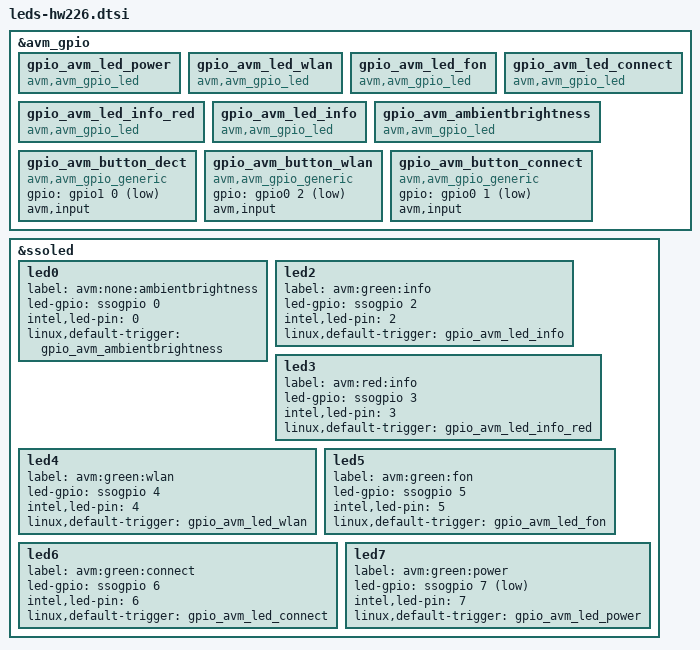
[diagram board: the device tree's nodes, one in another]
/* LEDs & Buttons für die 7590 und verwandte Boxen */

&avm_gpio {
	gpio_avm_led_power {
		compatible = "avm,avm_gpio_led";
	};
	gpio_avm_led_wlan {
		compatible = "avm,avm_gpio_led";
	};
	gpio_avm_led_fon {
		compatible = "avm,avm_gpio_led";
	};
	gpio_avm_led_connect {
		compatible = "avm,avm_gpio_led";
	};
	gpio_avm_led_info_red {
		compatible = "avm,avm_gpio_led";
	};
	gpio_avm_led_info {
		compatible = "avm,avm_gpio_led";
	};
	gpio_avm_ambientbrightness {
		compatible = "avm,avm_gpio_led";
	};
	gpio_avm_button_dect {
		compatible = "avm,avm_gpio_generic";
		gpio = <&gpio1 0 GPIO_ACTIVE_LOW>;
		avm,input;
	};
	gpio_avm_button_wlan {
		compatible = "avm,avm_gpio_generic";
		gpio = <&gpio0 2 GPIO_ACTIVE_LOW>;
		avm,input;
	};
	gpio_avm_button_connect {
		compatible = "avm,avm_gpio_generic";
		gpio = <&gpio0 1 GPIO_ACTIVE_LOW>;
		avm,input;
	};
};

&ssoled {
	status = "okay";

	led0 {
		/* 50% Duty Cycle Signal für die Helligkeitsmessung im FPGA */
		label = "avm:none:ambientbrightness";
		led-gpio = <&ssogpio 0 GPIO_ACTIVE_HIGH>;
		intel,led-pin = <0>;
		linux,default-trigger = "gpio_avm_ambientbrightness";
	};

	led2 {
		label = "avm:green:info";
		led-gpio = <&ssogpio 2 GPIO_ACTIVE_HIGH>;
		intel,led-pin = <2>;
		linux,default-trigger = "gpio_avm_led_info";
	};

	led3 {
		label = "avm:red:info";
		led-gpio = <&ssogpio 3 GPIO_ACTIVE_HIGH>;
		intel,led-pin = <3>;
		linux,default-trigger = "gpio_avm_led_info_red";
	};

	led4 {
		label = "avm:green:wlan";
		led-gpio = <&ssogpio 4 GPIO_ACTIVE_HIGH>;
		intel,led-pin = <4>;
		linux,default-trigger = "gpio_avm_led_wlan";
	};

	led5 {
		label = "avm:green:fon";
		led-gpio = <&ssogpio 5 GPIO_ACTIVE_HIGH>;
		intel,led-pin = <5>;
		linux,default-trigger = "gpio_avm_led_fon";
	};

	led6 {
		label = "avm:green:connect";
		led-gpio = <&ssogpio 6 GPIO_ACTIVE_HIGH>;
		intel,led-pin = <6>;
		linux,default-trigger = "gpio_avm_led_connect";
	};

	led7 {
		label = "avm:green:power";
		led-gpio = <&ssogpio 7 GPIO_ACTIVE_LOW>;
		intel,led-pin = <7>;
		linux,default-trigger = "gpio_avm_led_power";
	};
};
